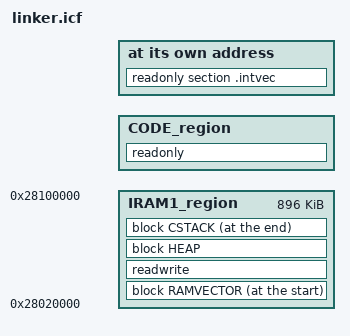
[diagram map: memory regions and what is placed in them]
/***************************************************************************//**
* \file xmc7200d_x8384_cm7_ota_int.icf
* \version 1.0.0
*
* Linker file for the IAR compiler.
*
* The main purpose of the linker script is to describe how the sections in the
* input files should be mapped into the output file, and to control the memory
* layout of the output file.
*
* \note The entry point is fixed and starts at 0x10000000. The valid application
* image should be placed there.
*
* \note The linker files included with the PDL template projects must be generic
* and handle all common use cases. Your project may not use every section
* defined in the linker files. In that case you may see warnings during the
* build process. In your project, you can simply comment out or remove the
* relevant code in the linker file.
*
********************************************************************************
* \copyright
* Copyright 2023 Cypress Semiconductor Corporation
* SPDX-License-Identifier: Apache-2.0
*
* Licensed under the Apache License, Version 2.0 (the "License");
* you may not use this file except in compliance with the License.
* You may obtain a copy of the License at
*
*     http://www.apache.org/licenses/LICENSE-2.0
*
* Unless required by applicable law or agreed to in writing, software
* distributed under the License is distributed on an "AS IS" BASIS,
* WITHOUT WARRANTIES OR CONDITIONS OF ANY KIND, either express or implied.
* See the License for the specific language governing permissions and
* limitations under the License.
*******************************************************************************/

/*###ICF### Section handled by ICF editor, don't touch! ****/
/*-Editor annotation file-*/
/* IcfEditorFile="$TOOLKIT_DIR$\config\ide\IcfEditor\cortex_v1_4.xml" */
/*-Specials-*/
define symbol __ICFEDIT_intvec_start__ = 0x00000000;

/* The symbols below define the location and size of blocks of memory in the target.
 * Use these symbols to specify the memory regions available for allocation.
 */

/* The following symbols control RAM and flash memory allocation for the CM7_0 core.
 * You can change the memory allocation by editing RAM and Flash symbols.
 * Your changes must be aligned with the corresponding symbols for CM0+ core in 'xmc7200d_x8384_cm0plus.icf'.
 */
/* RAM */
define symbol __ICFEDIT_region_IRAM1_start__ = 0x28020000; /* 0x20000 is reserved for cm0+ */
define symbol __ICFEDIT_region_IRAM1_end__   = 0x28100000;
/* Flash */
define symbol __ICFEDIT_region_IROM1_start__ = 0x10000000; /* 0x80000 is reserved for cm0+ */
define symbol __ICFEDIT_region_IROM1_end__   = 0x107F0000;

define symbol __ICFEDIT_region_EROM1_start__ = 0x0;
define symbol __ICFEDIT_region_EROM1_end__   = 0x0;
define symbol __ICFEDIT_region_EROM2_start__ = 0x0;
define symbol __ICFEDIT_region_EROM2_end__   = 0x0;
define symbol __ICFEDIT_region_EROM3_start__ = 0x0;
define symbol __ICFEDIT_region_EROM3_end__   = 0x0;


define symbol __ICFEDIT_region_ERAM1_start__ = 0x0;
define symbol __ICFEDIT_region_ERAM1_end__   = 0x0;
define symbol __ICFEDIT_region_ERAM2_start__ = 0x0;
define symbol __ICFEDIT_region_ERAM2_end__   = 0x0;
define symbol __ICFEDIT_region_ERAM3_start__ = 0x0;
define symbol __ICFEDIT_region_ERAM3_end__   = 0x0;

/*-Sizes-*/
if (!isdefinedsymbol(__STACK_SIZE)) {
  define symbol __ICFEDIT_size_cstack__ = 0x1000;
} else {
  define symbol __ICFEDIT_size_cstack__ = __STACK_SIZE;
}

/* Defines the minimum heap size. The actual heap size will be expanded to the end of the stack region */
if (!isdefinedsymbol(__HEAP_SIZE)) {
    define symbol __ICFEDIT_size_heap__ = 0x40000;
} else {
  define symbol __ICFEDIT_size_heap__ = __HEAP_SIZE;
}
/**** End of ICF editor section. ###ICF###*/

define symbol RAMVECTORS_ALIGNMENT          = 128;

define memory mem with size = 4G;
define region IRAM1_region = mem:[from __ICFEDIT_region_IRAM1_start__ to __ICFEDIT_region_IRAM1_end__];

define block CSTACK     with alignment = 8, size = __ICFEDIT_size_cstack__     { };
define block HEAP       with expanding size, alignment = 8, size = __ICFEDIT_size_heap__ { };
define block RAMVECTOR  with alignment = RAMVECTORS_ALIGNMENT { readwrite section .intvec_ram};

/*
    Arguments for OTA using MCUBoot -- will get from passed in Makefile:
    --config_def MCUBOOT_HEADER_SIZE=XXXX
    --config_def FLASH_AREA_IMG_1_PRIMARY_START=XXXX
    --config_def FLASH_AREA_IMG_1_PRIMARY_SIZE=XXXX
*/

define symbol FLASH_START = __ICFEDIT_region_IROM1_start__ + FLASH_AREA_IMG_1_PRIMARY_START + MCUBOOT_HEADER_SIZE;
define symbol FLASH_END   = FLASH_START + FLASH_AREA_IMG_1_PRIMARY_SIZE - MCUBOOT_HEADER_SIZE;

define region CODE_region = mem:[from FLASH_START to FLASH_END];

/*-Placement-*/

/*-Initializations-*/
initialize by copy { readwrite };
do not initialize  { section .noinit, section .intvec_ram };

/* Flash - Cortex-M7_0 application */
"intvec":
place at address mem:FLASH_START { readonly section .intvec };

"code":
place in            CODE_region   { readonly };

"intvec_ram":
place at start of   IRAM1_region { block RAMVECTOR };
"data":
place in            IRAM1_region { readwrite };
"heap":
place in            IRAM1_region { block HEAP };
"stack":
place at end of     IRAM1_region { block CSTACK };

keep {
        section .intvec,
        section .intvec_ram
     };

define exported symbol __ecc_init_sram_start_address = start(IRAM1_region);
define exported symbol __ecc_init_sram_end_address   = end(IRAM1_region);

/* EOF */
